VERSION ""

NS_ :

BS_:

BU_: XXX

BO_ 85 CID_BAQAIY: 8 XXX
 SG_ sig_xarave : 40|1@1+ (1,0) [0|1] "" XXX
 SG_ sig_itijmv : 56|8@1+ (1,0) [0|255] "" XXX

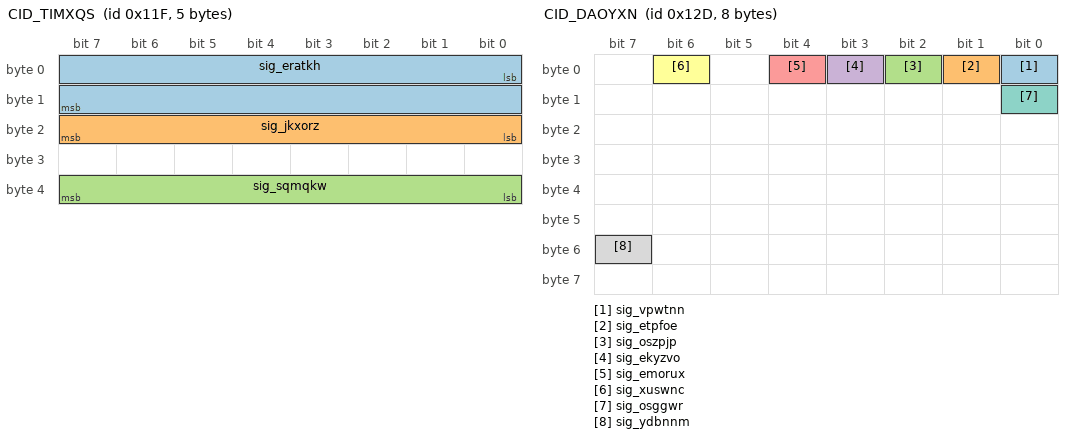
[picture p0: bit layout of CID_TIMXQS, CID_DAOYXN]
BO_ 287 CID_TIMXQS: 5 XXX
 SG_ sig_eratkh : 0|16@1- (0.1,0) [-450|450] "" XXX
 SG_ sig_jkxorz : 16|8@1+ (4,0) [0|1020] "" XXX
 SG_ sig_sqmqkw : 32|8@1+ (1,0) [0|255] "" XXX

BO_ 289 CID_NOQHGS: 8 XXX
 SG_ sig_ycbyac : 0|12@1+ (1,0) [0|255] "" XXX

BO_ 301 CID_DAOYXN: 8 XXX
 SG_ sig_vpwtnn : 0|1@0+ (1,0) [0|1] "" XXX
 SG_ sig_etpfoe : 1|1@0+ (1,0) [0|1] "" XXX
 SG_ sig_oszpjp : 2|1@0+ (1,0) [0|1] "" XXX
 SG_ sig_ekyzvo : 3|1@0+ (1,0) [0|1] "" XXX
 SG_ sig_emorux : 4|1@0+ (1,0) [0|1] "" XXX
 SG_ sig_xuswnc : 6|1@0+ (1,0) [0|1] "" XXX
 SG_ sig_osggwr : 8|1@0+ (1,0) [0|1] "" XXX
 SG_ sig_ydbnnm : 55|1@0+ (1,0) [0|1] "" XXX

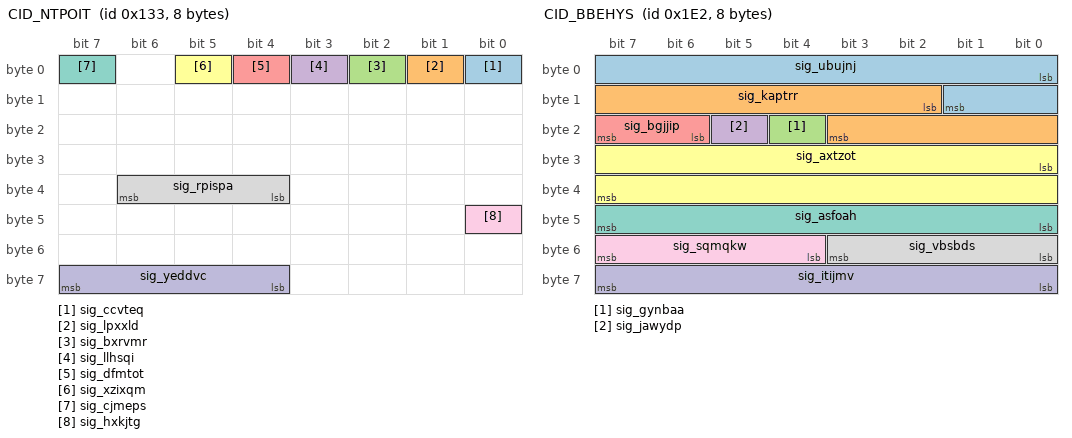
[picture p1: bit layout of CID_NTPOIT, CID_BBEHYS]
BO_ 307 CID_NTPOIT: 8 XXX
 SG_ sig_ccvteq : 0|1@0+ (1,0) [0|1] "" XXX
 SG_ sig_lpxxld : 1|1@1+ (1,0) [0|1] "" XXX
 SG_ sig_bxrvmr : 2|1@1+ (1,0) [0|1] "" XXX
 SG_ sig_llhsqi : 3|1@1+ (1,0) [0|1] "" XXX
 SG_ sig_dfmtot : 4|1@0+ (1,0) [0|1] "" XXX
 SG_ sig_xzixqm : 5|1@0+ (1,0) [0|1] "" XXX
 SG_ sig_cjmeps : 7|1@0+ (1,0) [0|1] "" XXX
 SG_ sig_rpispa : 36|3@1+ (1,0) [0|7] "" XXX
 SG_ sig_hxkjtg : 40|1@0+ (1,0) [0|1] "" XXX
 SG_ sig_yeddvc : 63|4@0+ (1,0) [0|15] "" XXX

BO_ 482 CID_BBEHYS: 8 XXX
 SG_ sig_ubujnj : 0|10@1- (0.01,0) [0|5] "" XXX
 SG_ sig_kaptrr : 10|10@1- (0.01,0) [-5|0] "" XXX
 SG_ sig_gynbaa : 20|1@0+ (1,0) [0|1] "" XXX
 SG_ sig_jawydp : 21|1@0+ (1,0) [0|1] "" XXX
 SG_ sig_bgjjip : 22|2@1+ (1,0) [0|1] "" XXX
 SG_ sig_axtzot : 24|16@1- (0.1,0) [-780|779.9] "" XXX
 SG_ sig_asfoah : 47|8@0+ (1,0) [0|255] "" XXX
 SG_ sig_vbsbds : 48|4@1+ (1,0) [0|15] "" XXX
 SG_ sig_sqmqkw : 52|4@1+ (1,0) [0|15] "" XXX
 SG_ sig_itijmv : 56|8@1+ (1,0) [0|255] "" XXX

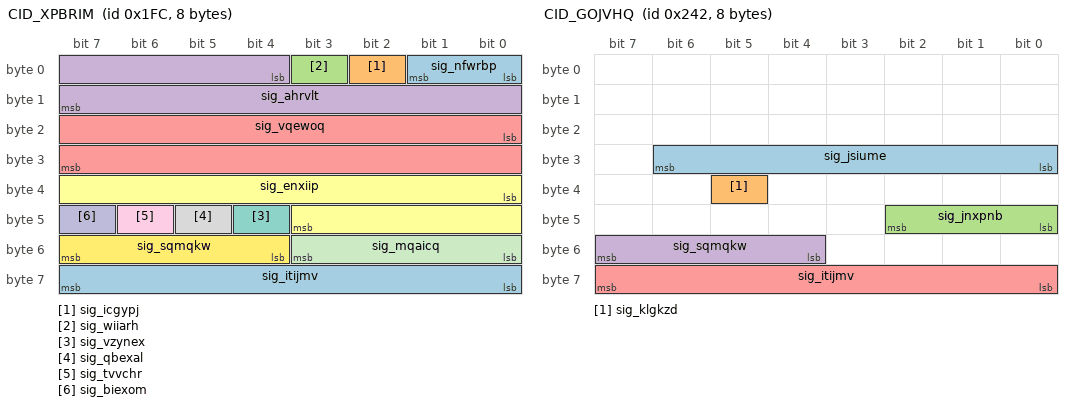
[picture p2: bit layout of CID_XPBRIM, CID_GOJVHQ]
BO_ 508 CID_XPBRIM: 8 XXX
 SG_ sig_nfwrbp : 0|2@1+ (1,0) [0|1] "" XXX
 SG_ sig_icgypj : 2|1@1+ (1,0) [0|1] "" XXX
 SG_ sig_wiiarh : 3|1@0+ (1,0) [0|1] "" XXX
 SG_ sig_ahrvlt : 4|12@1- (1,0) [-2048|2047] "" XXX
 SG_ sig_vqewoq : 16|16@1- (0.1,0) [-780|779.9] "Deg" XXX
 SG_ sig_enxiip : 32|12@1- (1,0) [0|63] "" XXX
 SG_ sig_vzynex : 44|1@0+ (1,0) [0|1] "" XXX
 SG_ sig_qbexal : 45|1@1+ (1,0) [0|255] "" XXX
 SG_ sig_tvvchr : 46|1@1+ (1,0) [0|1] "" XXX
 SG_ sig_biexom : 47|1@0+ (1,0) [0|3] "" XXX
 SG_ sig_mqaicq : 48|4@1+ (1,0) [0|15] "" XXX
 SG_ sig_sqmqkw : 52|4@1+ (1,0) [0|15] "" XXX
 SG_ sig_itijmv : 56|8@1+ (1,0) [0|255] "" XXX

BO_ 578 CID_GOJVHQ: 8 XXX
 SG_ sig_jsiume : 30|7@0+ (1,0) [0|127] "" XXX
 SG_ sig_klgkzd : 37|1@0+ (1,0) [0|1] "" XXX
 SG_ sig_jnxpnb : 40|3@1+ (1,0) [0|7] "" XXX
 SG_ sig_sqmqkw : 55|4@0+ (1,0) [0|15] "" XXX
 SG_ sig_itijmv : 56|8@1+ (1,0) [0|255] "" XXX

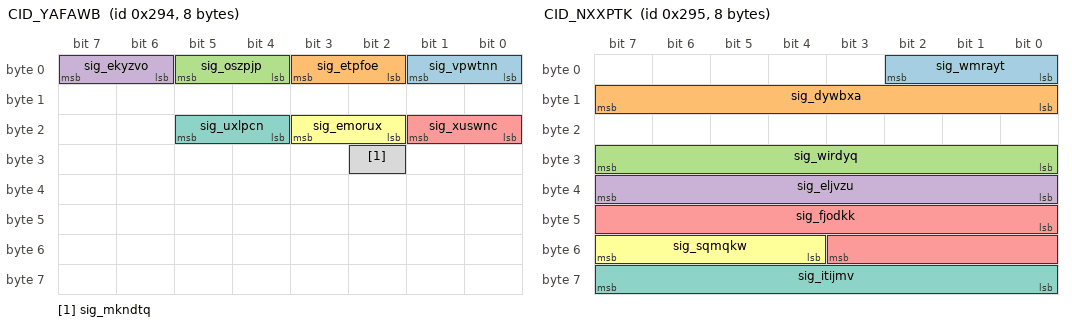
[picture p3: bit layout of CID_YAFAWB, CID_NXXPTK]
BO_ 660 CID_YAFAWB: 8 XXX
 SG_ sig_vpwtnn : 1|2@0+ (1,0) [0|3] "" XXX
 SG_ sig_etpfoe : 3|2@0+ (1,0) [0|3] "" XXX
 SG_ sig_oszpjp : 5|2@0+ (1,0) [0|3] "" XXX
 SG_ sig_ekyzvo : 7|2@0+ (1,0) [0|3] "" XXX
 SG_ sig_xuswnc : 17|2@0+ (1,0) [0|3] "" XXX
 SG_ sig_emorux : 19|2@0+ (1,0) [0|3] "" XXX
 SG_ sig_uxlpcn : 21|2@0+ (1,0) [0|3] "" XXX
 SG_ sig_mkndtq : 26|1@0+ (1,0) [0|1] "" XXX

BO_ 661 CID_NXXPTK: 8 XXX
 SG_ sig_wmrayt : 2|3@0+ (1,0) [0|7] "" XXX
 SG_ sig_dywbxa : 15|8@0+ (1,0) [0|255] "" XXX
 SG_ sig_wirdyq : 31|8@0+ (1,0) [0|255] "" XXX
 SG_ sig_eljvzu : 32|8@1+ (1,0) [0|255] "" XXX
 SG_ sig_fjodkk : 40|12@1+ (1,0) [0|255] "" XXX
 SG_ sig_sqmqkw : 52|4@1+ (1,0) [0|15] "" XXX
 SG_ sig_itijmv : 63|8@0+ (1,0) [0|255] "" XXX

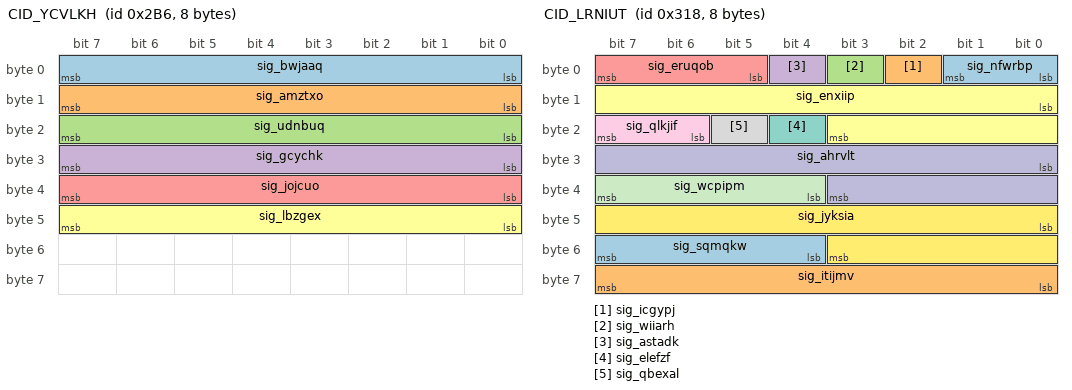
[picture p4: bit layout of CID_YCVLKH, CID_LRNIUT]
BO_ 694 CID_YCVLKH: 8 XXX
 SG_ sig_bwjaaq : 7|8@0+ (1,0) [0|255] "" XXX
 SG_ sig_amztxo : 15|8@0+ (1,0) [0|255] "" XXX
 SG_ sig_udnbuq : 23|8@0+ (1,0) [0|255] "" XXX
 SG_ sig_gcychk : 31|8@0+ (1,0) [0|255] "" XXX
 SG_ sig_jojcuo : 39|8@0+ (1,0) [0|255] "" XXX
 SG_ sig_lbzgex : 47|8@0+ (1,0) [0|255] "" XXX

BO_ 790 CID_DRBHMD: 8 XXX
 SG_ sig_odfhyz : 3|4@0+ (1,0) [0|1] "" XXX
 SG_ sig_gwtgje : 4|2@1+ (1,0) [0|3] "" XXX
 SG_ sig_zmzmkh : 6|2@1+ (1,0) [0|3] "" XXX
 SG_ sig_nzrbwk : 8|2@1+ (1,0) [0|3] "" XXX
 SG_ sig_yavzzz : 10|1@1+ (1,0) [0|1] "" XXX
 SG_ sig_vcakut : 11|4@1+ (1,0) [0|1] "" XXX
 SG_ sig_vgxztt : 15|1@0+ (1,0) [0|1] "" XXX
 SG_ sig_axtzot : 16|11@1- (1,0) [-1024|1023] "" XXX
 SG_ sig_gynbaa : 27|1@1+ (1,0) [0|1] "" XXX
 SG_ sig_jawydp : 28|1@1+ (1,0) [0|3] "" XXX
 SG_ sig_ytxqfj : 29|1@0+ (1,0) [0|1] "" XXX
 SG_ sig_bklqwu : 30|1@0+ (1,0) [0|1] "" XXX
 SG_ sig_mesdog : 31|1@0+ (1,0) [0|1] "" XXX
 SG_ sig_dlasbm : 32|2@1+ (1,0) [0|3] "" XXX
 SG_ sig_uarerm : 34|2@1+ (1,0) [0|3] "" XXX
 SG_ sig_dwembd : 36|4@1+ (1,0) [0|3] "" XXX
 SG_ sig_yvvtxh : 40|8@1+ (5,-5) [-5|1270] "" XXX
 SG_ sig_jemlnm : 49|2@0+ (1,0) [0|3] "" XXX
 SG_ sig_lvrvky : 51|2@0+ (1,0) [0|3] "" XXX
 SG_ sig_sqmqkw : 52|4@1+ (1,0) [0|15] "" XXX
 SG_ sig_itijmv : 56|8@1+ (1,0) [0|15] "" XXX

BO_ 792 CID_LRNIUT: 8 XXX
 SG_ sig_nfwrbp : 0|2@1+ (1,0) [0|1] "" XXX
 SG_ sig_icgypj : 2|1@1+ (1,0) [0|1] "" XXX
 SG_ sig_wiiarh : 3|1@1+ (1,0) [0|1] "" XXX
 SG_ sig_astadk : 4|1@1+ (1,0) [0|1] "" XXX
 SG_ sig_eruqob : 5|3@1+ (1,0) [0|1] "" XXX
 SG_ sig_enxiip : 8|12@1- (1,0) [-2048|2047] "" XXX
 SG_ sig_elefzf : 20|1@1+ (1,0) [0|1] "" XXX
 SG_ sig_qbexal : 21|1@1+ (1,0) [0|1] "" XXX
 SG_ sig_qlkjif : 22|2@1+ (1,0) [0|15] "" XXX
 SG_ sig_ahrvlt : 24|12@1- (1,0) [-2048|2047] "" XXX
 SG_ sig_wcpipm : 36|4@1+ (1,0) [0|15] "" XXX
 SG_ sig_jyksia : 40|12@1+ (1,0) [0|4095] "" XXX
 SG_ sig_sqmqkw : 52|4@1+ (1,0) [0|15] "" XXX
 SG_ sig_itijmv : 56|8@1+ (1,0) [0|255] "" XXX

BO_ 813 CID_NJGATH: 8 XXX
 SG_ sig_gpwohe : 0|9@1+ (0.5,0) [0|255.5] "" XXX
 SG_ sig_qexhos : 9|1@1+ (1,0) [0|1] "" XXX
 SG_ sig_boyaqk : 10|3@1+ (1,0) [0|7] "" XXX
 SG_ sig_zfkebe : 13|3@1+ (1,0) [0|7] "" XXX
 SG_ sig_giygdm : 16|1@1+ (1,0) [0|1] "" XXX
 SG_ sig_biukcw : 17|1@1+ (1,0) [0|1] "" XXX
 SG_ sig_wiiarh : 18|1@1+ (1,0) [0|1] "" XXX
 SG_ sig_zmmloj : 19|3@1+ (1,0) [0|1] "" XXX
 SG_ sig_ppcvjd : 22|1@0+ (1,0) [0|1] "" XXX
 SG_ sig_aozpcm : 23|1@0+ (1,0) [0|1] "" XXX
 SG_ sig_nzrbwk : 24|1@1+ (1,0) [0|1] "" XXX
 SG_ sig_ohkpoz : 25|7@1+ (1,0) [0|127] "" XXX
 SG_ sig_llocqv : 32|4@1+ (1,0) [0|15] "" XXX
 SG_ sig_dtwrdu : 36|12@1+ (1,0) [0|4095] "" XXX
 SG_ sig_sqmqkw : 48|4@1+ (1,0) [0|15] "" XXX
 SG_ sig_uwmryx : 55|4@0+ (1,0) [0|15] "" XXX
 SG_ sig_itijmv : 56|8@1+ (1,0) [0|255] "" XXX

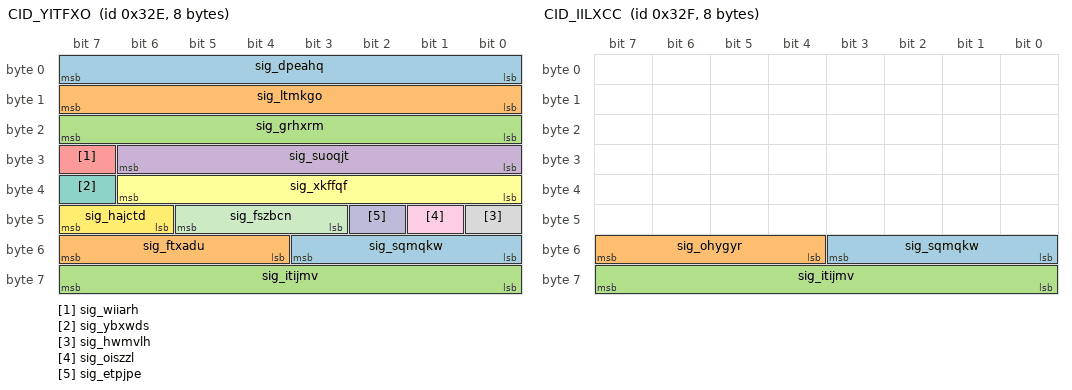
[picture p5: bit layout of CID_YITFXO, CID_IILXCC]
BO_ 814 CID_YITFXO: 8 XXX
 SG_ sig_dpeahq : 0|8@1+ (0.05,-5) [-100|155] "" XXX
 SG_ sig_ltmkgo : 8|8@1+ (0.05,-5) [0|1.26] "" XXX
 SG_ sig_grhxrm : 16|8@1+ (0.05,-5) [0|1.26] "" XXX
 SG_ sig_suoqjt : 24|7@1+ (0.2,0) [0|12.7] "" XXX
 SG_ sig_wiiarh : 31|1@0+ (1,0) [0|1] "" XXX
 SG_ sig_xkffqf : 32|7@1+ (0.2,-16) [0|12.7] "" XXX
 SG_ sig_ybxwds : 39|1@0+ (1,0) [0|1] "" XXX
 SG_ sig_hwmvlh : 40|1@0+ (1,0) [0|1] "" XXX
 SG_ sig_oiszzl : 41|1@0+ (1,0) [0|1] "" XXX
 SG_ sig_etpjpe : 42|1@1+ (1,0) [0|3] "" XXX
 SG_ sig_fszbcn : 45|3@0+ (1,0) [0|1] "" XXX
 SG_ sig_hajctd : 46|2@1+ (1,0) [0|3] "" XXX
 SG_ sig_sqmqkw : 48|4@1+ (1,0) [0|15] "" XXX
 SG_ sig_ftxadu : 55|4@0+ (1,0) [0|15] "" XXX
 SG_ sig_itijmv : 56|8@1+ (1,0) [0|255] "" XXX

BO_ 815 CID_IILXCC: 8 XXX
 SG_ sig_sqmqkw : 48|4@1+ (1,0) [0|15] "" XXX
 SG_ sig_ohygyr : 55|4@0+ (1,0) [0|15] "" XXX
 SG_ sig_itijmv : 56|8@1+ (1,0) [0|255] "" XXX

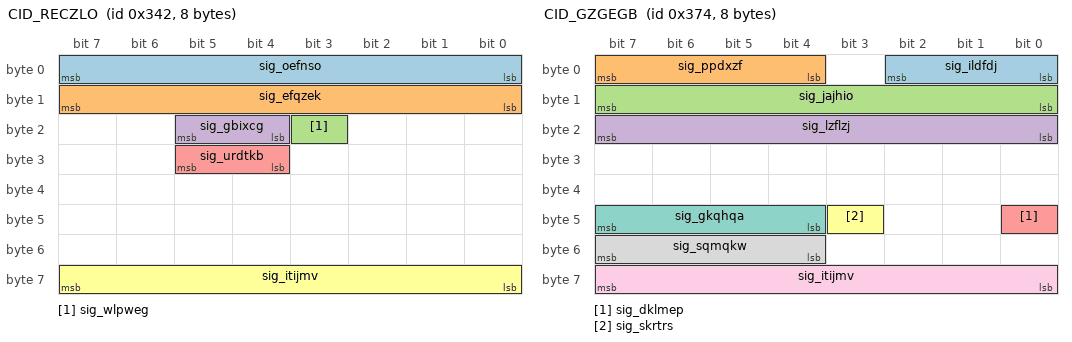
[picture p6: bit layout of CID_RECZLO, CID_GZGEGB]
BO_ 834 CID_RECZLO: 8 XXX
 SG_ sig_oefnso : 0|8@1+ (0.01,0) [0|2.55] "" XXX
 SG_ sig_efqzek : 8|8@1+ (0.01,0) [0|2.55] "" XXX
 SG_ sig_wlpweg : 19|1@1+ (1,0) [0|1] "" XXX
 SG_ sig_gbixcg : 20|2@1+ (1,0) [0|255] "" XXX
 SG_ sig_urdtkb : 28|2@1+ (1,0) [0|1] "" XXX
 SG_ sig_itijmv : 56|8@1+ (1,0) [0|255] "" XXX

BO_ 884 CID_GZGEGB: 8 MRR
 SG_ sig_ildfdj : 2|3@0+ (1,0) [0|3] "" MRR
 SG_ sig_ppdxzf : 7|4@0+ (1,0) [0|15] "" MRR
 SG_ sig_jajhio : 15|8@0+ (0.1,-12) [0|255] "" MRR
 SG_ sig_lzflzj : 23|8@0+ (1,-100) [0|255] "" MRR
 SG_ sig_dklmep : 40|1@0+ (1,0) [0|3] "" MRR
 SG_ sig_skrtrs : 43|1@0+ (1,0) [0|1] "" XXX
 SG_ sig_gkqhqa : 44|4@1+ (1,0) [0|15] "" XXX
 SG_ sig_sqmqkw : 52|4@1+ (1,0) [0|15] "" MRR
 SG_ sig_itijmv : 56|8@1+ (1,0) [0|255] "" MRR

BO_ 944 CID_UKSAUB: 8 XXX
 SG_ sig_ilwqmb : 1|2@0+ (1,0) [0|3] "" XXX
 SG_ sig_vvafio : 2|1@0+ (1,0) [0|1] "" XXX
 SG_ sig_pkltmx : 4|2@0+ (1,0) [0|3] "" XXX
 SG_ sig_bnufjf : 5|1@0+ (1,0) [0|1] "" XXX
 SG_ sig_akwwhn : 6|1@0+ (1,0) [0|1] "" XXX
 SG_ sig_hixfct : 7|1@0+ (1,0) [0|1] "" XXX
 SG_ sig_nebipj : 8|1@0+ (1,0) [0|1] "" XXX
 SG_ sig_cdaqja : 11|3@0+ (1,0) [0|7] "" XXX
 SG_ sig_dgspjl : 12|1@0+ (1,0) [0|1] "" XXX
 SG_ sig_tvjvox : 14|2@0+ (1,0) [0|3] "" XXX
 SG_ sig_aejnmh : 15|1@0+ (1,0) [0|1] "" XXX
 SG_ sig_uifedr : 16|1@0+ (1,0) [0|1] "" XXX
 SG_ sig_efglsg : 18|2@0+ (1,0) [0|3] "" XXX
 SG_ sig_ufrett : 19|1@0+ (1,0) [0|1] "" XXX
 SG_ sig_krhpjd : 23|4@0+ (1,0) [0|15] "" XXX
 SG_ sig_poqsur : 24|28@1+ (1,0) [0|268435455] "" XXX
 SG_ sig_sqmqkw : 52|4@1+ (1,0) [0|15] "" XXX
 SG_ sig_itijmv : 56|8@1+ (1,0) [0|255] "" XXX

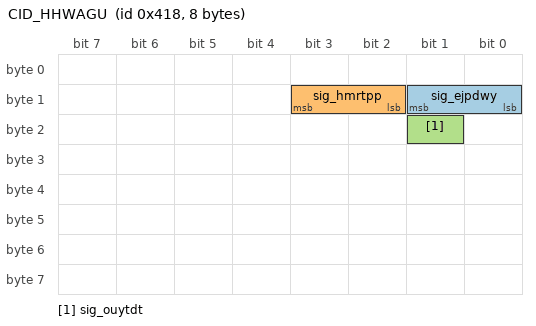
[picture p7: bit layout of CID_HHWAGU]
BO_ 1048 CID_HHWAGU: 8 XXX
 SG_ sig_ejpdwy : 9|2@0+ (1,0) [0|1] "" XXX
 SG_ sig_hmrtpp : 11|2@0+ (1,0) [0|1] "" XXX
 SG_ sig_ouytdt : 17|1@0+ (1,0) [0|1] "" XXX

VAL_ 578 sig_jnxpnb 4 "D" 2 "R" 3 "N" 1 "P";
VAL_ 790 sig_odfhyz 11 "AutoFullBeamActive" 2 "AutoFullBeamInactive";
VAL_ 790 sig_gwtgje 0 "GRAY" 1 "GREEN" 2 "YELLOW" 3 "RED";
VAL_ 790 sig_zmzmkh 3 "ALARM_AND_LKA" 2 "LKA" 1 "ALARM" 0 "DISABLE";
VAL_ 790 sig_uarerm 0 "GRAY" 1 "GREEN" 2 "YELLOW" 3 "RED";
VAL_ 790 sig_jemlnm 0 "VIBRATION" 1 "AUDIO" 2 "AUDIO_AND_VIBRATION";
VAL_ 792 sig_nfwrbp 0 "NotReady" 1 "Ready" 2 "Active" 3 "TemporaryFail";
VAL_ 813 sig_boyaqk 4 "4BAR" 3 "3BAR" 2 "2BAR" 1 "1BAR";
VAL_ 813 sig_zmmloj 0 "OFF" 2 "ACC_ON" 3 "ACC_ACTIVE" 5 "FORCE_ACCEL" 7 "ERROR";
VAL_ 813 sig_ohkpoz 36 "ACC_ERROR" 22 "OVERRIDE" 12 "ENGAGE" 8 "DISENGAGE" 20 "ACC_ON" 32 "ACC_OFF" 48 "CHECK_GEAR_D" 16 "FORCE_ACCEL" 0 "NONE";
VAL_ 814 sig_fszbcn 0 "Off" 1 "Passive" 2 "StandBy" 3 "ActiveControl" 4 "BrakeOnly" 5 "Override" 6 "Standstill" 7 "Failure";
VAL_ 814 sig_hajctd 0 "Softoff" 1 "Fastoff" 2 "Immediateoff" 3 "Initial";
VAL_ 834 sig_gbixcg 2 "SPORT" 1 "ECO" 0 "SNOW";
VAL_ 834 sig_urdtkb 3 "HEV" 2 "FORCE_EV" 1 "EV";
VAL_ 944 sig_pkltmx 0 "NOTPRESSED" 1 "DOWN_SETSPEED" 3 "UP_RESETSPEED";
